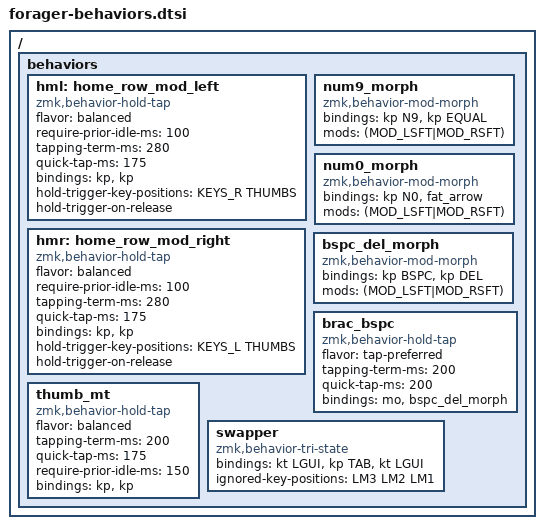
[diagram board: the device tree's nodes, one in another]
// "#binding-cells" can't be written inside a function-like macro (# would
// be the stringify operator), so it comes from this object-like macro.
#define MOD_MORPH_CORE compatible = "zmk,behavior-mod-morph"; #binding-cells = <0>

#define BRAC_FN(name, tap, fkey)                                               \
    name: name {                                                               \
        MOD_MORPH_CORE;                                                        \
        bindings = <tap>, <&kp fkey>;                                          \
        mods = <(MOD_LSFT|MOD_RSFT)>;                                          \
    };

/ {
    behaviors {
        hml: home_row_mod_left {
            compatible = "zmk,behavior-hold-tap";
            #binding-cells = <2>;
            flavor = "balanced";
            require-prior-idle-ms = <100>;
            tapping-term-ms = <280>;
            quick-tap-ms = <175>;
            bindings = <&kp>, <&kp>;
            hold-trigger-key-positions = <KEYS_R THUMBS>;
            hold-trigger-on-release;
        };

        hmr: home_row_mod_right {
            compatible = "zmk,behavior-hold-tap";
            #binding-cells = <2>;
            flavor = "balanced";
            require-prior-idle-ms = <100>;
            tapping-term-ms = <280>;
            quick-tap-ms = <175>;
            bindings = <&kp>, <&kp>;
            hold-trigger-key-positions = <KEYS_L THUMBS>;
            hold-trigger-on-release;
        };

        // NUM already reuses N9/N0 for "(" and ")" via Shift on a US layout,
        // duplicating what BRAC's dedicated LPAR/RPAR already provide - morph
        // them into something not available elsewhere instead.
        num9_morph: num9_morph {
            compatible = "zmk,behavior-mod-morph";
            #binding-cells = <0>;
            bindings = <&kp N9>, <&kp EQUAL>;
            mods = <(MOD_LSFT|MOD_RSFT)>;
        };

        num0_morph: num0_morph {
            compatible = "zmk,behavior-mod-morph";
            #binding-cells = <0>;
            bindings = <&kp N0>, <&fat_arrow>;
            mods = <(MOD_LSFT|MOD_RSFT)>;
        };

        // RH0: tap = Backspace, Shift+tap = Delete, hold = BRAC (the F-keys
        // live on BRAC+Shift, see brac_f* below).
        bspc_del_morph: bspc_del_morph {
            compatible = "zmk,behavior-mod-morph";
            #binding-cells = <0>;
            bindings = <&kp BSPC>, <&kp DEL>;
            mods = <(MOD_LSFT|MOD_RSFT)>;
        };

        brac_bspc: brac_bspc {
            compatible = "zmk,behavior-hold-tap";
            #binding-cells = <2>;
            flavor = "tap-preferred";
            tapping-term-ms = <200>;
            quick-tap-ms = <200>;
            bindings = <&mo>, <&bspc_del_morph>;
        };

        // RH1: tap = Space, hold = Option/Alt. A typing streak (another key
        // within require-prior-idle-ms) always resolves to Space, so fast
        // "word<space>word" rolls never turn into Alt+letter; a deliberate
        // Alt chord usually starts after a short pause anyway. RALT rather
        // than LALT so AltGr-based layouts (e.g. Polish on Windows) work too.
        thumb_mt: thumb_mt {
            compatible = "zmk,behavior-hold-tap";
            #binding-cells = <2>;
            flavor = "balanced";
            tapping-term-ms = <200>;
            quick-tap-ms = <175>;
            require-prior-idle-ms = <150>;
            bindings = <&kp>, <&kp>;
        };

        // BRAC + Shift = former FUN layer. Each left-hand BRAC key is a
        // mod-morph: plain press = bracket (or nothing), Shift = F-key. Shift
        // is masked from the F-key (no keep-mods), so it sends a bare Fn;
        // other mods (e.g. Ctrl from BRAC's right-hand row) pass through.
        BRAC_FN(brac_f12, &none,     F12)
        BRAC_FN(brac_f7,  &none,     F7)
        BRAC_FN(brac_f8,  &none,     F8)
        BRAC_FN(brac_f9,  &kp LPAR,  F9)
        BRAC_FN(brac_f11, &none,     F11)
        BRAC_FN(brac_f4,  &kp LT,    F4)
        BRAC_FN(brac_f5,  &kp GT,    F5)
        BRAC_FN(brac_f6,  &kp LBRC,  F6)
        BRAC_FN(brac_f10, &none,     F10)
        BRAC_FN(brac_f1,  &none,     F1)
        BRAC_FN(brac_f2,  &none,     F2)
        BRAC_FN(brac_f3,  &kp LBKT,  F3)

        // App switcher, run by combos on NUM (combo_swapper*): the first
        // D+F presses ⌘Tab and keeps ⌘ down, every further D+F is another
        // Tab, S+D goes backwards. Letting go of the NUM thumb - or any
        // other key - releases ⌘ and switches to the selected app.
        // Needs github.com/urob/zmk-tri-state (config/west.yml).
        swapper: swapper {
            compatible = "zmk,behavior-tri-state";
            #binding-cells = <0>;
            bindings = <&kt LGUI>, <&kp TAB>, <&kt LGUI>;
            // the raw presses of S, D and F behind the combos must not end it
            ignored-key-positions = <LM3 LM2 LM1>;
        };
    };
};
